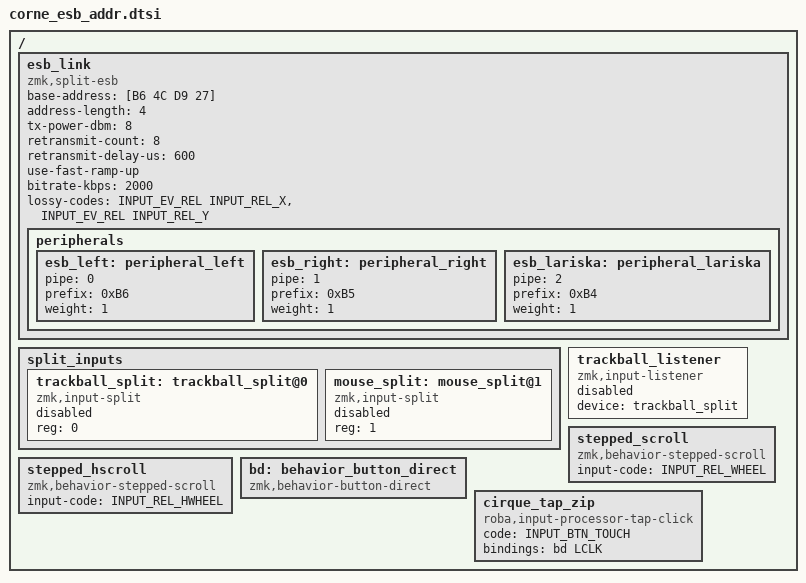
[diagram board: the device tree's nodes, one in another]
/*
 * Shared ESB link identity for the corne_esb dongle and all peripherals.
 * Every side must include the same base address, channel set, and peripheral
 * table. Each peripheral overlay selects its own entry with zmk,esb-self.
 *
 * The RF identity here is DISTINCT from both the roBakesb system
 * (base [E7 E3 A7 E8], prefixes E7/E6/E5) and the charybdis_esb system
 * (base [C4 D1 B2 9A], prefixes C4/C3/C2) so all three can run side by side
 * without colliding.
 *
 * The trackball_listener is disabled here; the dongle overlay enables it.
 * The (optional) cirque right overlay assigns device = <&glidepoint0> to
 * trackball_split. The (optional) lariska peripheral assigns
 * device = <&mou0> to mouse_split.
 */

#include <zephyr/dt-bindings/input/input-event-codes.h>
#include <dt-bindings/zmk/pointing.h>

/ {
    esb_link: esb_link {
        compatible = "zmk,split-esb";
        base-address = [B6 4C D9 27];
        address-length = <4>;
        peripherals {
            esb_left: peripheral_left {
                pipe = <0>;
                prefix = <0xB6>;
                weight = <1>;
            };

            esb_right: peripheral_right {
                pipe = <1>;
                prefix = <0xB5>;
                weight = <1>;
            };

            esb_lariska: peripheral_lariska {
                pipe = <2>;
                prefix = <0xB4>;
                weight = <1>;
            };
        };

        tx-power-dbm = <8>;
        retransmit-count = <8>;
        retransmit-delay-us = <600>;
        use-fast-ramp-up;
        bitrate-kbps = <2000>;
        lossy-codes
            = <INPUT_EV_REL INPUT_REL_X>
            , <INPUT_EV_REL INPUT_REL_Y>;
    };

    split_inputs {
        #address-cells = <1>;
        #size-cells = <0>;

        trackball_split: trackball_split@0 {
            compatible = "zmk,input-split";
            reg = <0>;
            status = "disabled";
        };

        mouse_split: mouse_split@1 {
            compatible = "zmk,input-split";
            reg = <1>;
            status = "disabled";
        };
    };

    trackball_listener: trackball_listener {
        compatible = "zmk,input-listener";
        status = "disabled";
        device = <&trackball_split>;
    };

    /* Defined here so all targets (dongle + every peripheral) resolve
     * &stepped_scroll from the shared corne_esb.keymap. The dongle's overlay
     * also adds stepped_scroll_il which routes the events to HID. */
    stepped_scroll: stepped_scroll {
        compatible = "zmk,behavior-stepped-scroll";
        #binding-cells = <1>;
        input-code = <INPUT_REL_WHEEL>;
    };

    /* Horizontal variant of stepped_scroll. Routed to HID by stepped_hscroll_il
     * in the dongle overlay. */
    stepped_hscroll: stepped_hscroll {
        compatible = "zmk,behavior-stepped-scroll";
        #binding-cells = <1>;
        input-code = <INPUT_REL_HWHEEL>;
    };

    /* Drain-aware HID button behavior (zmk-behavior-button-direct): every
     * release zeroes the button's HID press count. A release lost over ESB
     * (retransmits exhausted under bad RSSI) leaves &mkp's count stuck >0 —
     * button held until dongle power-cycle; with &bd the next release
     * self-heals. Declared here so the shared keymap resolves &bd on every
     * corne_esb target. */
    bd: behavior_button_direct {
        compatible = "zmk,behavior-button-direct";
        #binding-cells = <1>;
    };

    /* Cirque tap gesture (BTN_TOUCH from the pinnacle driver) → left click
     * via &bd instead of input_listener's raw button bookkeeping, so a lost
     * touch-release cannot wedge the click. Wired into trackball_listener's
     * input-processors by the dongle overlay.
     *
     * Custom processor (src/input_processor_tap_click.c), NOT the stock
     * zmk,input-processor-behaviors: the stock one returns STOP, which drops
     * the sync flag the pinnacle driver carries only on BTN_TOUCH — the
     * listener then never flushes REL_X/Y and the pointer freezes. This one
     * invokes &bd on touch transitions and lets the (neutralized) event
     * continue so sync still flushes motion. */
    cirque_tap_zip: cirque_tap_zip {
        compatible = "roba,input-processor-tap-click";
        #input-processor-cells = <0>;
        code = <INPUT_BTN_TOUCH>;
        bindings = <&bd LCLK>;
    };
};
